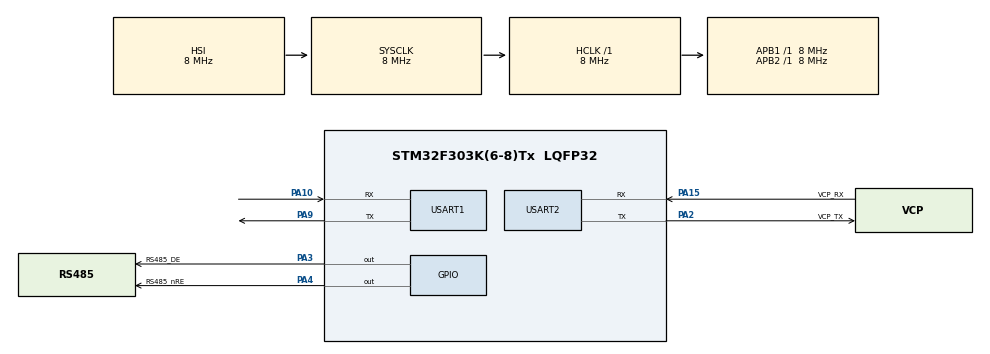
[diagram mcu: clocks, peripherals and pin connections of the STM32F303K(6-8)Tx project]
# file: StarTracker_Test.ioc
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Dma.Request0=USART1_RX
Dma.USART1_RX.0.Direction=DMA_PERIPH_TO_MEMORY
Dma.USART1_RX.0.Instance=DMA1_Channel5
Dma.USART1_RX.0.MemDataAlignment=DMA_MDATAALIGN_BYTE
Dma.USART1_RX.0.MemInc=DMA_MINC_ENABLE
Dma.USART1_RX.0.Mode=DMA_NORMAL
Dma.USART1_RX.0.PeriphDataAlignment=DMA_PDATAALIGN_BYTE
Dma.USART1_RX.0.PeriphInc=DMA_PINC_DISABLE
Dma.USART1_RX.0.Priority=DMA_PRIORITY_LOW
FREERTOS.Tasks01=defaultTask,0,128,StartDefaultTask,Default,NULL,Dynamic,NULL,NULL
Mcu.Family=STM32F3
Mcu.Name=STM32F303K(6-8)Tx
Mcu.Package=LQFP32
NVIC.DMA1_Channel5_IRQn=true\:5\:0\:false\:false\:true\:true\:false\:true\:true
NVIC.PriorityGroup=NVIC_PRIORITYGROUP_4
NVIC.TIM1_UP_TIM16_IRQn=true\:15\:0\:false\:false\:true\:false\:false\:true\:true
NVIC.TimeBase=TIM1_UP_TIM16_IRQn
NVIC.TimeBaseIP=TIM1
PA10.Mode=Asynchronous
PA10.Signal=USART1_RX
PA13.GPIO_Label=SWDIO
PA13.Mode=Serial_Wire
PA13.Signal=SYS_JTMS-SWDIO
PA14.GPIO_Label=SWCLK
PA14.Mode=Serial_Wire
PA14.Signal=SYS_JTCK-SWCLK
PA15.GPIO_Label=VCP_RX
PA15.Mode=Asynchronous
PA15.Signal=USART2_RX
PA2.GPIO_Label=VCP_TX
PA2.Mode=Asynchronous
PA2.Signal=USART2_TX
PA3.GPIO_Label=RS485_DE
PA3.Signal=GPIO_Output
PA4.GPIO_Label=RS485_nRE
PA4.Signal=GPIO_Output
PA9.Mode=Asynchronous
PA9.Signal=USART1_TX
PF0\ /\ OSC_IN.GPIO_Label=MCO
PF0\ /\ OSC_IN.Mode=HSE-External-Clock-Source
PF0\ /\ OSC_IN.Signal=RCC_OSC_IN
ProjectManager.HeapSize=0x200
ProjectManager.StackSize=0x400
ProjectManager.TargetToolchain=STM32CubeIDE
RCC.AHBFreq_Value=8000000
RCC.APB1Freq_Value=8000000
RCC.APB2Freq_Value=8000000
RCC.CortexFreq_Value=8000000
RCC.HSE_VALUE=8000000
RCC.HSI_VALUE=8000000
RCC.SYSCLKFreq_VALUE=8000000
USART1.VirtualMode-Asynchronous=VM_ASYNC
USART2.VirtualMode-Asynchronous=VM_ASYNC
VP_FREERTOS_VS_CMSIS_V1.Mode=CMSIS_V1
VP_SYS_VS_tim1.Mode=TIM1
board=NUCLEO-F303K8

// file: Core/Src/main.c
/* USER CODE BEGIN Header */
/**
  ******************************************************************************
  * @file           : main.c
  * @brief          : Main program body
  ******************************************************************************
  * @attention
  *
  * Copyright (c) 2026 STMicroelectronics.
  * All rights reserved.
  *
  * This software is licensed under terms that can be found in the LICENSE file
  * in the root directory of this software component.
  * If no LICENSE file comes with this software, it is provided AS-IS.
  *
  ******************************************************************************
  */
/* USER CODE END Header */
#include "main.h"
#include "cmsis_os.h"

/* USER CODE BEGIN Includes */
#include "rs485_hal.h"
#include "st16_test.h"
/* USER CODE END Includes */

UART_HandleTypeDef huart1;
UART_HandleTypeDef huart2;
DMA_HandleTypeDef hdma_usart1_rx;

osThreadId defaultTaskHandle;

void SystemClock_Config(void);
static void MX_GPIO_Init(void);
static void MX_DMA_Init(void);
static void MX_USART1_UART_Init(void);
static void MX_USART2_UART_Init(void);
void StartDefaultTask(void const * argument);

int main(void)
{

  /* MCU Configuration--------------------------------------------------------*/

  /* Reset of all peripherals, Initializes the Flash interface and the Systick. */
  HAL_Init();

  /* Configure the system clock */
  SystemClock_Config();

  /* Initialize all configured peripherals */
  MX_GPIO_Init();
  MX_DMA_Init();
  MX_USART1_UART_Init();
  MX_USART2_UART_Init();
  /* USER CODE BEGIN 2 */
  BaseType_t status;

  status = xTaskCreate(vTaskST16Test,"ST16Test",
		  configMINIMAL_STACK_SIZE,NULL,
		  tskIDLE_PRIORITY, NULL);
  /* USER CODE END 2 */

  /* Create the thread(s) */
  /* definition and creation of defaultTask */
  osThreadDef(defaultTask, StartDefaultTask, osPriorityNormal, 0, 128);
  defaultTaskHandle = osThreadCreate(osThread(defaultTask), NULL);

  /* Start scheduler */
  osKernelStart();

  /* We should never get here as control is now taken by the scheduler */

  /* Infinite loop */
  while (1)
  {

  }
}

void SystemClock_Config(void)
{
  RCC_OscInitTypeDef RCC_OscInitStruct = {0};
  RCC_ClkInitTypeDef RCC_ClkInitStruct = {0};
  RCC_PeriphCLKInitTypeDef PeriphClkInit = {0};

  /** Initializes the RCC Oscillators according to the specified parameters
  * in the RCC_OscInitTypeDef structure.
  */
  RCC_OscInitStruct.OscillatorType = RCC_OSCILLATORTYPE_HSI;
  RCC_OscInitStruct.HSIState = RCC_HSI_ON;
  RCC_OscInitStruct.HSICalibrationValue = RCC_HSICALIBRATION_DEFAULT;
  RCC_OscInitStruct.PLL.PLLState = RCC_PLL_NONE;
  if (HAL_RCC_OscConfig(&RCC_OscInitStruct) != HAL_OK)
  {
    Error_Handler();
  }

  /** Initializes the CPU, AHB and APB buses clocks
  */
  RCC_ClkInitStruct.ClockType = RCC_CLOCKTYPE_HCLK|RCC_CLOCKTYPE_SYSCLK
                              |RCC_CLOCKTYPE_PCLK1|RCC_CLOCKTYPE_PCLK2;
  RCC_ClkInitStruct.SYSCLKSource = RCC_SYSCLKSOURCE_HSI;
  RCC_ClkInitStruct.AHBCLKDivider = RCC_SYSCLK_DIV1;
  RCC_ClkInitStruct.APB1CLKDivider = RCC_HCLK_DIV1;
  RCC_ClkInitStruct.APB2CLKDivider = RCC_HCLK_DIV1;

  if (HAL_RCC_ClockConfig(&RCC_ClkInitStruct, FLASH_LATENCY_0) != HAL_OK)
  {
    Error_Handler();
  }
  PeriphClkInit.PeriphClockSelection = RCC_PERIPHCLK_USART1;
  PeriphClkInit.Usart1ClockSelection = RCC_USART1CLKSOURCE_PCLK1;
  if (HAL_RCCEx_PeriphCLKConfig(&PeriphClkInit) != HAL_OK)
  {
    Error_Handler();
  }
}

static void MX_USART1_UART_Init(void)
{

  huart1.Instance = USART1;
  huart1.Init.BaudRate = 38400;
  huart1.Init.WordLength = UART_WORDLENGTH_8B;
  huart1.Init.StopBits = UART_STOPBITS_1;
  huart1.Init.Parity = UART_PARITY_NONE;
  huart1.Init.Mode = UART_MODE_TX_RX;
  huart1.Init.HwFlowCtl = UART_HWCONTROL_NONE;
  huart1.Init.OverSampling = UART_OVERSAMPLING_16;
  huart1.Init.OneBitSampling = UART_ONE_BIT_SAMPLE_DISABLE;
  huart1.AdvancedInit.AdvFeatureInit = UART_ADVFEATURE_NO_INIT;
  if (HAL_UART_Init(&huart1) != HAL_OK)
  {
    Error_Handler();
  }

}

static void MX_USART2_UART_Init(void)
{

  huart2.Instance = USART2;
  huart2.Init.BaudRate = 38400;
  huart2.Init.WordLength = UART_WORDLENGTH_8B;
  huart2.Init.StopBits = UART_STOPBITS_1;
  huart2.Init.Parity = UART_PARITY_NONE;
  huart2.Init.Mode = UART_MODE_TX_RX;
  huart2.Init.HwFlowCtl = UART_HWCONTROL_NONE;
  huart2.Init.OverSampling = UART_OVERSAMPLING_16;
  huart2.Init.OneBitSampling = UART_ONE_BIT_SAMPLE_DISABLE;
  huart2.AdvancedInit.AdvFeatureInit = UART_ADVFEATURE_NO_INIT;
  if (HAL_UART_Init(&huart2) != HAL_OK)
  {
    Error_Handler();
  }

}

static void MX_DMA_Init(void)
{

  /* DMA controller clock enable */
  __HAL_RCC_DMA1_CLK_ENABLE();

  /* DMA interrupt init */
  /* DMA1_Channel5_IRQn interrupt configuration */
  HAL_NVIC_SetPriority(DMA1_Channel5_IRQn, 5, 0);
  HAL_NVIC_EnableIRQ(DMA1_Channel5_IRQn);

}

static void MX_GPIO_Init(void)
{
  GPIO_InitTypeDef GPIO_InitStruct = {0};

  /* GPIO Ports Clock Enable */
  __HAL_RCC_GPIOF_CLK_ENABLE();
  __HAL_RCC_GPIOA_CLK_ENABLE();

  /*Configure GPIO pin Output Level */
  HAL_GPIO_WritePin(GPIOA, RS485_DE_Pin|RS485_nRE_Pin, GPIO_PIN_RESET);

  /*Configure GPIO pins : RS485_DE_Pin RS485_nRE_Pin */
  GPIO_InitStruct.Pin = RS485_DE_Pin|RS485_nRE_Pin;
  GPIO_InitStruct.Mode = GPIO_MODE_OUTPUT_PP;
  GPIO_InitStruct.Pull = GPIO_NOPULL;
  GPIO_InitStruct.Speed = GPIO_SPEED_FREQ_LOW;
  HAL_GPIO_Init(GPIOA, &GPIO_InitStruct);

}

/* USER CODE BEGIN 4 */
// Retarget printf to USART2
int _write(int file, char *ptr, int len) {
    (void)file;  // Unused

    // Transmit each character via USART2
    for (int i = 0; i < len; i++) {
        HAL_UART_Transmit(&huart2, (uint8_t *)&ptr[i], 1, HAL_MAX_DELAY);
    }

    return len;
}
/* USER CODE END 4 */

void StartDefaultTask(void const * argument)
{
  for(;;)
  {
    osDelay(1);
  }
}

void HAL_TIM_PeriodElapsedCallback(TIM_HandleTypeDef *htim)
{
  if (htim->Instance == TIM1)
  {
    HAL_IncTick();
  }
}

void Error_Handler(void)
{
  __disable_irq();
  while (1)
  {
  }
}
